VERSION "0.6.1"

NS_ :

BS_:

BU_:

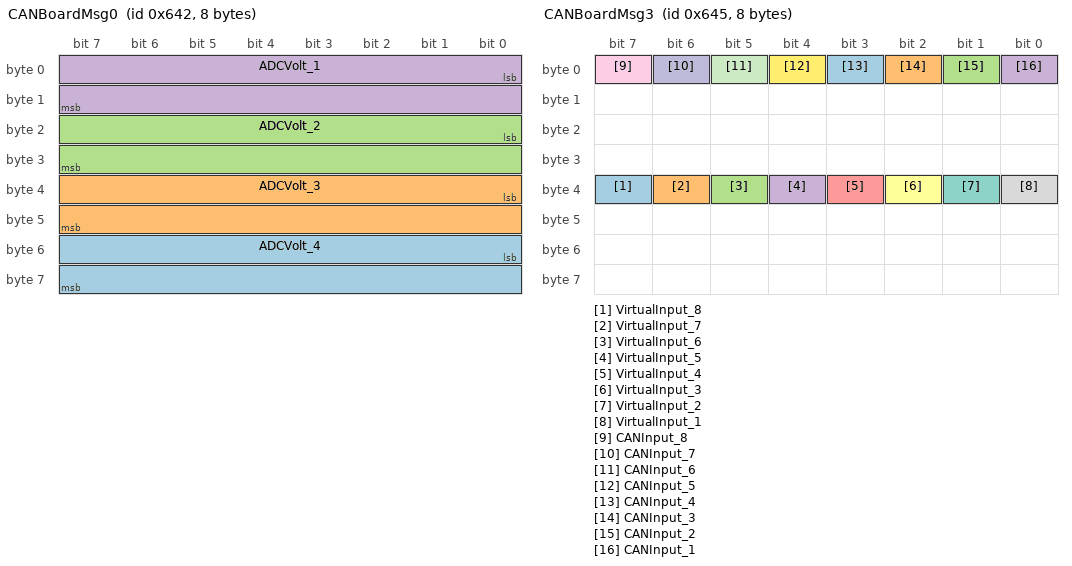
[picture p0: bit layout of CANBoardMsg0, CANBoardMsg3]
BO_ 1602 CANBoardMsg0: 8 Vector__XXX
 SG_ ADCVolt_4 : 48|16@1+ (0.001,0) [0|0] "" Vector__XXX
 SG_ ADCVolt_3 : 32|16@1+ (0.001,0) [0|0] "" Vector__XXX
 SG_ ADCVolt_2 : 16|16@1+ (0.001,0) [0|0] "" Vector__XXX
 SG_ ADCVolt_1 : 0|16@1+ (0.001,0) [0|0] "" Vector__XXX

BO_ 1603 CANBoardMsg1: 8 Vector__XXX
 SG_ BoardTemp : 48|16@1+ (1,0) [0|125] "" Vector__XXX
 SG_ ADCVolt5 : 0|16@1+ (0.001,0) [0|6] "" Vector__XXX

BO_ 1604 CANBoardMsg2: 8 Vector__XXX
 SG_ Heartbeat : 56|8@1+ (1,0) [0|255] "" Vector__XXX
 SG_ DigitalOutput_4 : 51|1@1+ (1,0) [0|0] "" Vector__XXX
 SG_ DigitalOutput_3 : 50|1@1+ (1,0) [0|0] "" Vector__XXX
 SG_ DigitalOutput_2 : 49|1@1+ (1,0) [0|0] "" Vector__XXX
 SG_ DigitalOutput_1 : 48|1@1+ (1,0) [0|0] "" Vector__XXX
 SG_ AnalogSwitch_5 : 44|1@1+ (1,0) [0|0] "" Vector__XXX
 SG_ AnalogSwitch_4 : 43|1@1+ (1,0) [0|0] "" Vector__XXX
 SG_ AnalogSwitch_3 : 42|1@1+ (1,0) [0|0] "" Vector__XXX
 SG_ AnalogSwitch_2 : 41|1@1+ (1,0) [0|0] "" Vector__XXX
 SG_ AnalogSwitch_1 : 40|1@1+ (1,0) [0|0] "" Vector__XXX
 SG_ DigitalInput_8 : 39|1@1+ (1,0) [0|0] "" Vector__XXX
 SG_ DigitalInput_7 : 38|1@1+ (1,0) [0|0] "" Vector__XXX
 SG_ DigitalInput_6 : 37|1@1+ (1,0) [0|0] "" Vector__XXX
 SG_ DigitalInput_5 : 36|1@1+ (1,0) [0|0] "" Vector__XXX
 SG_ DigitalInput_4 : 35|1@1+ (1,0) [0|0] "" Vector__XXX
 SG_ DigitalInput_3 : 34|1@1+ (1,0) [0|0] "" Vector__XXX
 SG_ DigitalInput_2 : 33|1@1+ (1,0) [0|0] "" Vector__XXX
 SG_ DigitalInput_1 : 32|1@1+ (1,0) [0|0] "" Vector__XXX
 SG_ Timer_4 : 31|1@1+ (1,0) [0|0] "" Vector__XXX
 SG_ Timer_3 : 30|1@1+ (1,0) [0|0] "" Vector__XXX
 SG_ Timer_2 : 29|1@1+ (1,0) [0|0] "" Vector__XXX
 SG_ Timer_1 : 28|1@1+ (1,0) [0|0] "" Vector__XXX
 SG_ Flash_4 : 27|1@1+ (1,0) [0|0] "" Vector__XXX
 SG_ Flash_3 : 26|1@1+ (1,0) [0|0] "" Vector__XXX
 SG_ Flash_2 : 25|1@1+ (1,0) [0|0] "" Vector__XXX
 SG_ Flash_1 : 24|1@1+ (1,0) [0|0] "" Vector__XXX
 SG_ RotarySwitch_5 : 16|4@1+ (1,0) [0|0] "" Vector__XXX
 SG_ RotarySwitch_4 : 12|4@1+ (1,0) [0|0] "" Vector__XXX
 SG_ RotarySwitch_3 : 8|4@1+ (1,0) [0|0] "" Vector__XXX
 SG_ RotarySwitch_2 : 4|4@1+ (1,0) [0|0] "" Vector__XXX
 SG_ RotarySwitch_1 : 0|4@1+ (1,0) [0|0] "" Vector__XXX

BO_ 1605 CANBoardMsg3: 8 Vector__XXX
 SG_ VirtualInput_8 : 39|1@1+ (1,0) [0|0] "" Vector__XXX
 SG_ VirtualInput_7 : 38|1@1+ (1,0) [0|0] "" Vector__XXX
 SG_ VirtualInput_6 : 37|1@1+ (1,0) [0|0] "" Vector__XXX
 SG_ VirtualInput_5 : 36|1@1+ (1,0) [0|0] "" Vector__XXX
 SG_ VirtualInput_4 : 35|1@1+ (1,0) [0|0] "" Vector__XXX
 SG_ VirtualInput_3 : 34|1@1+ (1,0) [0|0] "" Vector__XXX
 SG_ VirtualInput_2 : 33|1@1+ (1,0) [0|0] "" Vector__XXX
 SG_ VirtualInput_1 : 32|1@1+ (1,0) [0|0] "" Vector__XXX
 SG_ CANInput_8 : 7|1@1+ (1,0) [0|0] "" Vector__XXX
 SG_ CANInput_7 : 6|1@1+ (1,0) [0|0] "" Vector__XXX
 SG_ CANInput_6 : 5|1@1+ (1,0) [0|0] "" Vector__XXX
 SG_ CANInput_5 : 4|1@1+ (1,0) [0|0] "" Vector__XXX
 SG_ CANInput_4 : 3|1@1+ (1,0) [0|0] "" Vector__XXX
 SG_ CANInput_3 : 2|1@1+ (1,0) [0|0] "" Vector__XXX
 SG_ CANInput_2 : 1|1@1+ (1,0) [0|0] "" Vector__XXX
 SG_ CANInput_1 : 0|1@1+ (1,0) [0|0] "" Vector__XXX

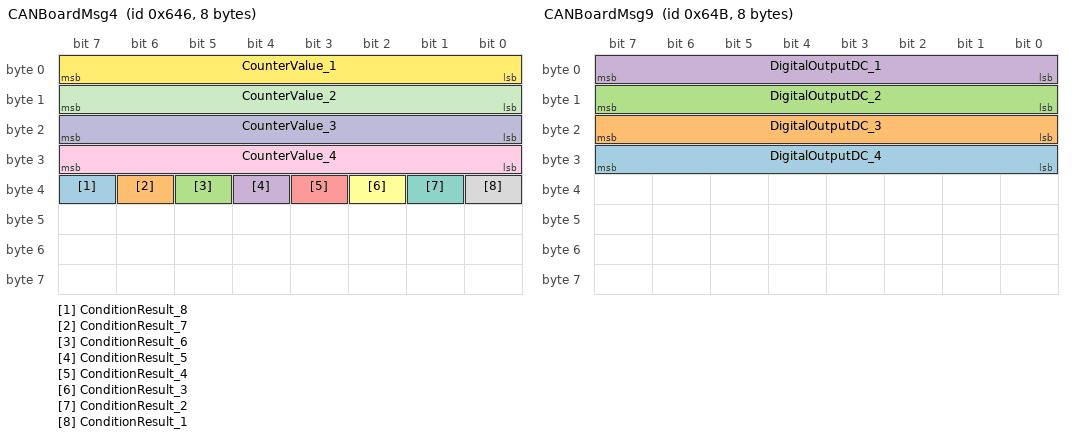
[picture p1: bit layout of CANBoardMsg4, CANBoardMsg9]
BO_ 1606 CANBoardMsg4: 8 Vector__XXX
 SG_ ConditionResult_8 : 39|1@1+ (1,0) [0|0] "" Vector__XXX
 SG_ ConditionResult_7 : 38|1@1+ (1,0) [0|0] "" Vector__XXX
 SG_ ConditionResult_6 : 37|1@1+ (1,0) [0|0] "" Vector__XXX
 SG_ ConditionResult_5 : 36|1@1+ (1,0) [0|0] "" Vector__XXX
 SG_ ConditionResult_4 : 35|1@1+ (1,0) [0|0] "" Vector__XXX
 SG_ ConditionResult_3 : 34|1@1+ (1,0) [0|0] "" Vector__XXX
 SG_ ConditionResult_2 : 33|1@1+ (1,0) [0|0] "" Vector__XXX
 SG_ ConditionResult_1 : 32|1@1+ (1,0) [0|0] "" Vector__XXX
 SG_ CounterValue_4 : 24|8@1+ (1,0) [0|0] "" Vector__XXX
 SG_ CounterValue_3 : 16|8@1+ (1,0) [0|0] "" Vector__XXX
 SG_ CounterValue_2 : 8|8@1+ (1,0) [0|0] "" Vector__XXX
 SG_ CounterValue_1 : 0|8@1+ (1,0) [0|0] "" Vector__XXX

BO_ 1607 CANBoardMsg5: 8 Vector__XXX
 SG_ CANInputValue_2 : 32|32@1+ (1,0) [0|0] "" Vector__XXX
 SG_ CANInputValue_1 : 0|32@1+ (1,0) [0|0] "" Vector__XXX

BO_ 1608 CANBoardMsg6: 8 Vector__XXX
 SG_ CANInputValue_4 : 32|32@1+ (1,0) [0|0] "" Vector__XXX
 SG_ CANInputValue_3 : 0|32@1+ (1,0) [0|0] "" Vector__XXX

BO_ 1609 CANBoardMsg7: 8 Vector__XXX
 SG_ CANInputValue_6 : 32|32@1+ (1,0) [0|0] "" Vector__XXX
 SG_ CANInputValue_5 : 0|32@1+ (1,0) [0|0] "" Vector__XXX

BO_ 1610 CANBoardMsg8: 8 Vector__XXX
 SG_ CANInputValue_8 : 32|32@1+ (1,0) [0|0] "" Vector__XXX
 SG_ CANInputValue_7 : 0|32@1+ (1,0) [0|0] "" Vector__XXX

BO_ 1613 CANBoardMsg11: 8 Vector__XXX
 SG_ PidOutput_2 : 16|16@1- (0.1,0) [0|0] "" Vector__XXX
 SG_ PidOutput_1 : 0|16@1- (0.1,0) [0|0] "" Vector__XXX

BO_ 1612 CANBoardMsg10: 8 Vector__XXX
 SG_ WakeFromSleep : 63|1@1+ (1,0) [0|1] "" Vector__XXX
 SG_ WakeOther : 59|1@1+ (1,0) [0|1] "" Vector__XXX
 SG_ WakeUsb : 58|1@1+ (1,0) [0|1] "" Vector__XXX
 SG_ WakeDigIn : 57|1@1+ (1,0) [0|1] "" Vector__XXX
 SG_ WakeCan : 56|1@1+ (1,0) [0|1] "" Vector__XXX
 SG_ IgnDashShutdown : 54|1@1+ (1,0) [0|1] "" Vector__XXX
 SG_ IgnReady : 53|1@1+ (1,0) [0|1] "" Vector__XXX
 SG_ IgnRunning : 52|1@1+ (1,0) [0|1] "" Vector__XXX
 SG_ IgnStarter : 51|1@1+ (1,0) [0|1] "" Vector__XXX
 SG_ IgnDash : 50|1@1+ (1,0) [0|1] "" Vector__XXX
 SG_ IgnAccessory : 49|1@1+ (1,0) [0|1] "" Vector__XXX
 SG_ IgnIgnition : 48|1@1+ (1,0) [0|1] "" Vector__XXX
 SG_ IgnSleepCountdown : 32|16@1+ (1,0) [0|3600] "" Vector__XXX
 SG_ IgnLink : 24|8@1+ (1,0) [0|3] "" Vector__XXX
 SG_ IgnSleepStatus : 16|8@1+ (1,0) [0|7] "" Vector__XXX
 SG_ IgnDashState : 8|8@1+ (1,0) [0|4] "" Vector__XXX
 SG_ IgnRole : 4|4@1+ (1,0) [0|2] "" Vector__XXX
 SG_ IgnState : 0|4@1+ (1,0) [0|3] "" Vector__XXX

BO_ 1611 CANBoardMsg9: 8 Vector__XXX
 SG_ DigitalOutputDC_4 : 24|8@1+ (1,0) [0|0] "%" Vector__XXX
 SG_ DigitalOutputDC_3 : 16|8@1+ (1,0) [0|0] "%" Vector__XXX
 SG_ DigitalOutputDC_2 : 8|8@1+ (1,0) [0|0] "%" Vector__XXX
 SG_ DigitalOutputDC_1 : 0|8@1+ (1,0) [0|0] "%" Vector__XXX

VAL_ 1612 IgnLink 0 "NotFollower" 1 "Ok" 2 "Lost" 3 "SyncIdInvalid" ;
VAL_ 1612 IgnSleepStatus 0 "Disabled" 1 "Awake" 2 "Counting" 3 "Following" 4 "WaitingDash" 5 "Held" 6 "Quiet" 7 "Sleep" ;
VAL_ 1612 IgnDashState 0 "Off" 1 "On" 2 "Grace" 3 "Halting" 4 "Restart" ;
VAL_ 1612 IgnRole 0 "Main" 1 "Follower" 2 "Standalone" ;
VAL_ 1612 IgnState 0 "Off" 1 "On" 2 "Cranking" 3 "Running" ;
